# ATA5702M322 device description
Architecture: AVR8; Family: megaAVR
Registers are 8-bit, access not given, no defined reset value unless marked. A register's access mark holds for its fields unless they carry their own. Offsets are from the block's base; [hi:lo] are bit positions; {n}, {i} and the like mark numbered series; 'fields as' and 'values as' point back to an identical list.

## GPIOREGS_DVCC
Instances: GPIOREGS_DVCC 0x00
0x20 GPIOR0 — General Purpose I/O Register 0
0x44 GPIOR1 — General Purpose I/O Register 1
0x45 GPIOR2 — General Purpose I/O Register 2

## GPIOREGS_LFVCC
Instances: GPIOREGS_LFVCC 0x00
{0x17F+i} GPIOR{i} (i=3..8) — General Purpose I/O Register {i}

## INT
Instances: INT 0x00
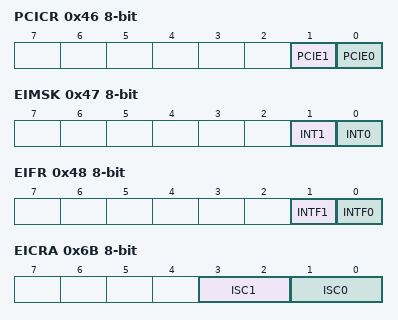
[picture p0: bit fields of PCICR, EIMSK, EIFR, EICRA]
0x46 PCICR — Pin change Interrupt control Register
  [1] PCIE1 — Pin Change Interrupt Enable 1
  [0] PCIE0 — Pin Change Interrupt Enable 0
0x47 EIMSK — External Interrupt Mask Register
  [1] INT1 — External Interrupt Request 1 Enable
  [0] INT0 — External Interrupt Request 0 Enable
0x48 EIFR — External Interrupt Flag Register
  [1] INTF1 — External Interrupt Flag 1
  [0] INTF0 — External Interrupt Flag 0
0x6B EICRA — External Interrupt control Register
  [3:2] ISC1 — Interrupt Sense Control 1
    0=LOW_LEVEL_OF_INTX; 1=LOGICAL_CHANGE_OF_INTX; 2=FALLING_EDGE_OF_INTX; 3=RISING_EDGE_OF_INTX
  [1:0] ISC0 — Interrupt Sense Control 0
    values as ISC1
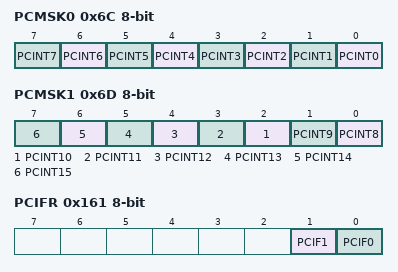
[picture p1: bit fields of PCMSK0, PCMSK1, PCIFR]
0x6C PCMSK0 — Pin change Mask Register 0
  [n] PCINT{n} (n=0..7) — Pin Change Enable Mask bit {n}
0x6D PCMSK1 — Pin change Mask Register 1
  [n-8] PCINT{n} (n=8..15) — Pin Change Enable Mask bit {n}
0x161 PCIFR — Pin change Interrupt flag Register
  [1] PCIF1 — Pin Change Interrupt Flag 1
  [0] PCIF0 — Pin Change Interrupt Flag 0

## LED
Instances: LED 0x00
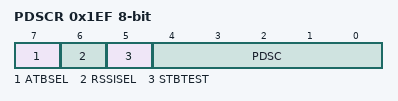
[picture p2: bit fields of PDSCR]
0x1EF PDSCR — Pad Driver Strength Control Register
  [7] ATBSEL — Analog Testbus Select
  [6] RSSISEL — Testmode Enable for RSSI Measurement
  [5] STBTEST — Standby Test Enable
  [4:0] PDSC — Pad Driver Strength Control

## LF_FIFO
Instances: LF_FIFO 0x00
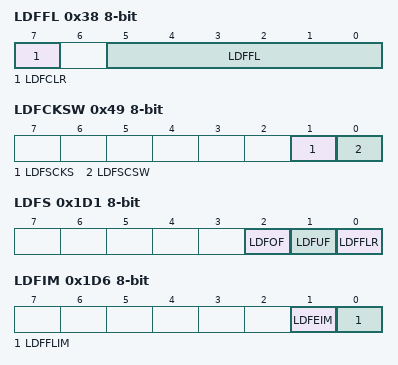
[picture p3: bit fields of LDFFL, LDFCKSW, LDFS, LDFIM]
0x38 LDFFL — LF Data FIFO Fill Level Register
  [7] LDFCLR — LF Data FIFO Clear
  [5:0] LDFFL — LF Data Fifo Fill Level
0x39 LDFD — LF Data FIFO Data Register
0x49 LDFCKSW — LF Data FIFO Clock Switch Register
  [1] LDFSCKS — LF Data FIFO Synchronous Clock Status
  [0] LDFSCSW — LF Data FIFO Synchronous Clock Switch
0x1D1 LDFS — LF Data FIFO Status Register
  [2] LDFOF — LF Data FIFO OverFlow flag
  [1] LDFUF — LF Data FIFO UnderFlow flag
  [0] LDFFLR — LF Data FIFO Fill-Level Reached flag
0x1D3 LDFWP — LF Data FIFO Write Pointer
  [5:0] LDFWP — LF Data FIFO Write Pointer bit 5
0x1D4 LDFRP — LF Data FIFO Read Pointer
  [5:0] LDFRP
0x1D6 LDFIM — LF Data FIFO Interrupt Mask Register
  [1] LDFEIM — LF Data FIFO Error Interrupt Mask
  [0] LDFFLIM — LF Data FIFO Fill-level Interrupt Mask
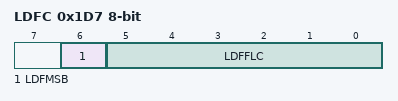
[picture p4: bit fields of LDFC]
0x1D7 LDFC — LF Data FIFO Configuration Register
  [6] LDFMSB — LF Data FIFO MSB alignment bit
  [5:0] LDFFLC — LF Data FIFO Fill-Level Configuration

## LF_PROTOCOL_HANDLER
Instances: LF_PROTOCOL_HANDLER 0x00
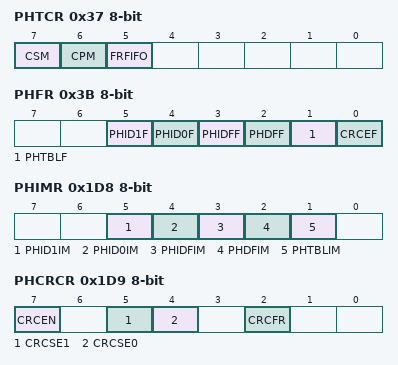
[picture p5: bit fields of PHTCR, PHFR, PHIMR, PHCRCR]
0x37 PHTCR — PH Telegram Configuration Register
  [7] CSM — Continue or Single receive Mode
  [6] CPM — Continuous Pattern Mode
  [5] FRFIFO — ID Frame stored in FIFO
0x3B PHFR — Protocol Handler Flag Register
  [5] PHID1F — Protocol Handler IDentifier 1 Flag
  [4] PHID0F — Protocol Handler IDentifier 0 Flag
  [3] PHIDFF — Protocol Handler ID Frame Flag
  [2] PHDFF — Protocol Handler Date Frame Flag
  [1] PHTBLF — Protocol Handler Telegram Bit Length Flag
  [0] CRCEF — PH CRC Error Status Flag
0x188 PHBCRR — Protocol Handler Bit Counter Read Register
0x190 PHID0 32-bit
0x194 PHID0L bits used 5:0 — PH Identifier 0 Length Register
0x195 PHID1 32-bit
0x199 PHID1L bits used 5:0 — PH Identifier 1 Length Register
0x19A PHIDFR — Protocol Handler ID Frame Register
0x1A4 PHTBLR — Protocol Handler Telegram Bit Length Register
0x1A5 PHDFR — Protocol Handler Data Frame end Register
0x1D8 PHIMR — Protocol Handler Interrupt Mask Register
  [5] PHID1IM — Protocol Handler IDentifier 1 Interrupt Mask
  [4] PHID0IM — Protocol Handler IDentifier 0 Interrupt Mask
  [3] PHIDFIM — Protocol Handler ID Frame Interrupt Mask
  [2] PHDFIM — Protocol Handler Date Frame Interrupt Mask
  [1] PHTBLIM — Protocol Handler Telegram Bit Length Interrupt Mask
0x1D9 PHCRCR — Protocol Handler CRC Control Register
  [7] CRCEN — CRC Enable
  [5] CRCSE1 — CRC size bit 1
  [4] CRCSE0 — CRC size bit 0
  [2] CRCFR — CRC ID Frame
0x1DA PHCST 16-bit — PH CRC Start Value Register
0x1DC PHCRP 16-bit — PH CRC Polynomial Register
0x1DE PHCSR 16-bit — PH CRC Checksum Register
